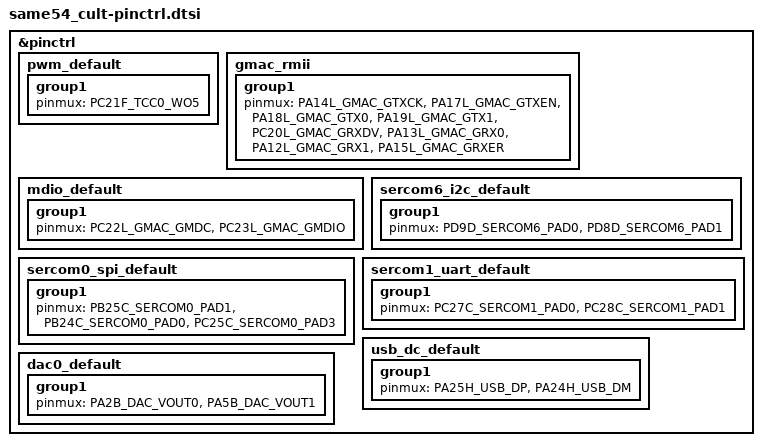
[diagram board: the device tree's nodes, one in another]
/*
 * Copyright (c) 2022, Gerson Fernando Budke <nandojve@gmail.com>
 * SPDX-License-Identifier: Apache-2.0
 */

#include <dt-bindings/pinctrl/same54p-pinctrl.h>

&pinctrl {
	pwm_default: pwm_default {
		group1 {
			pinmux = <PC21F_TCC0_WO5>;
		};
	};

	gmac_rmii: gmac_rmii {
		group1 {
			pinmux = <PA14L_GMAC_GTXCK>,
				 <PA17L_GMAC_GTXEN>,
				 <PA18L_GMAC_GTX0>,
				 <PA19L_GMAC_GTX1>,
				 <PC20L_GMAC_GRXDV>,
				 <PA13L_GMAC_GRX0>,
				 <PA12L_GMAC_GRX1>,
				 <PA15L_GMAC_GRXER>;
		};
	};

	mdio_default: mdio_default {
		group1 {
			pinmux = <PC22L_GMAC_GMDC>,
				 <PC23L_GMAC_GMDIO>;
		};
	};

	sercom6_i2c_default: sercom6_i2c_default {
		group1 {
			pinmux = <PD9D_SERCOM6_PAD0>,
				 <PD8D_SERCOM6_PAD1>;
		};
	};

	sercom0_spi_default: sercom0_spi_default {
		group1 {
			pinmux = <PB25C_SERCOM0_PAD1>,
				 <PB24C_SERCOM0_PAD0>,
				 <PC25C_SERCOM0_PAD3>;
		};
	};

	sercom1_uart_default: sercom1_uart_default {
		group1 {
			pinmux = <PC27C_SERCOM1_PAD0>,
				 <PC28C_SERCOM1_PAD1>;
		};
	};

	usb_dc_default: usb_dc_default {
		group1 {
			pinmux = <PA25H_USB_DP>,
				 <PA24H_USB_DM>;
		};
	};

	dac0_default: dac0_default {
		group1 {
			pinmux = <PA2B_DAC_VOUT0>,
				 <PA5B_DAC_VOUT1>;
		};
	};
};
